VERSION ""

NS_ :

BS_:

BU_:
VAL_TABLE_ vtSig_SystemMode 3 "Autonomous Mode" 2 "Lateral Control" 1 "Longitudinal Control" 0 "Off" ;
VAL_TABLE_ vtGearPosition 12 "IntermediatePosition" 11 "SportsMode" 10 "6" 9 "5" 8 "4" 7 "3" 6 "2" 5 "1" 4 "D" 3 "L" 2 "R" 1 "N" 0 "P" ;

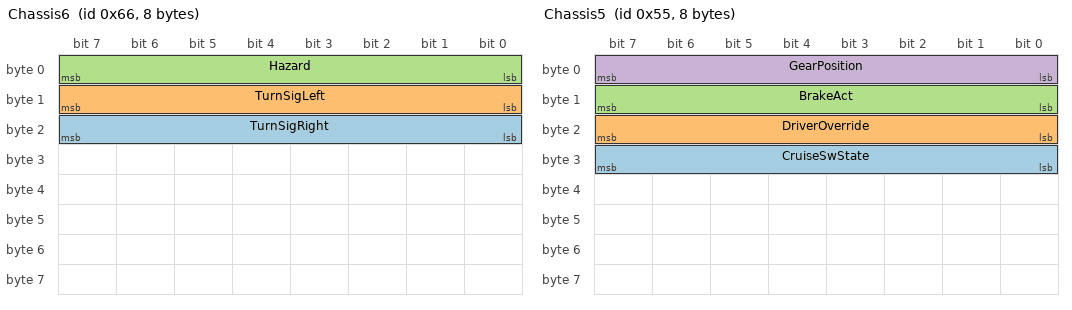
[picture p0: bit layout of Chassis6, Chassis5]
BO_ 102 Chassis6: 8 Vector__XXX
 SG_ TurnSigRight : 16|8@1+ (1,0) [0|0] "" Vector__XXX
 SG_ TurnSigLeft : 8|8@1+ (1,0) [0|0] "" Vector__XXX
 SG_ Hazard : 0|8@1+ (1,0) [0|0] "" Vector__XXX

BO_ 85 Chassis5: 8 Vector__XXX
 SG_ CruiseSwState : 24|8@1+ (1,0) [0|0] "" Vector__XXX
 SG_ DriverOverride : 16|8@1+ (1,0) [0|2] "" Vector__XXX
 SG_ BrakeAct : 8|8@1+ (1,0) [0|0] "" Vector__XXX
 SG_ GearPosition : 0|8@1+ (1,0) [0|0] "" Vector__XXX

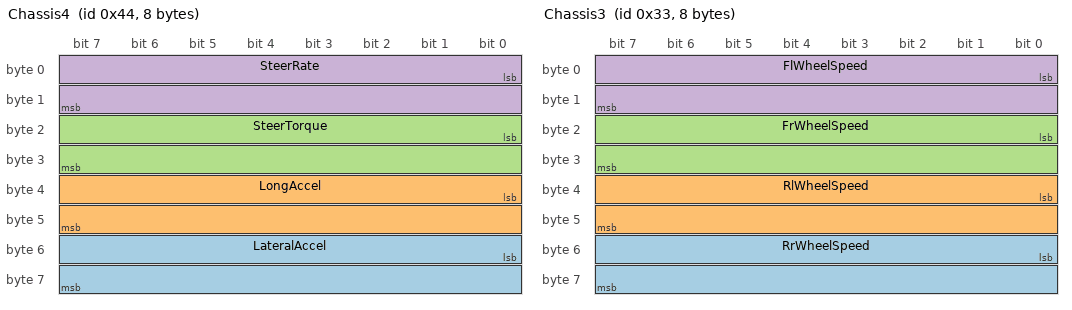
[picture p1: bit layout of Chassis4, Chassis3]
BO_ 68 Chassis4: 8 Vector__XXX
 SG_ LateralAccel : 48|16@1- (0.01,0) [0|0] "" Vector__XXX
 SG_ LongAccel : 32|16@1- (0.01,0) [0|0] "" Vector__XXX
 SG_ SteerTorque : 16|16@1- (0.01,0) [0|0] "N/m" Vector__XXX
 SG_ SteerRate : 0|16@1+ (1,0) [0|0] "deg/s" Vector__XXX

BO_ 51 Chassis3: 8 Vector__XXX
 SG_ RrWheelSpeed : 48|16@1+ (0.1,0) [0|0] "kph" Vector__XXX
 SG_ RlWheelSpeed : 32|16@1+ (0.1,0) [0|0] "kph" Vector__XXX
 SG_ FrWheelSpeed : 16|16@1+ (0.1,0) [0|0] "kph" Vector__XXX
 SG_ FlWheelSpeed : 0|16@1+ (0.1,0) [0|0] "kph" Vector__XXX

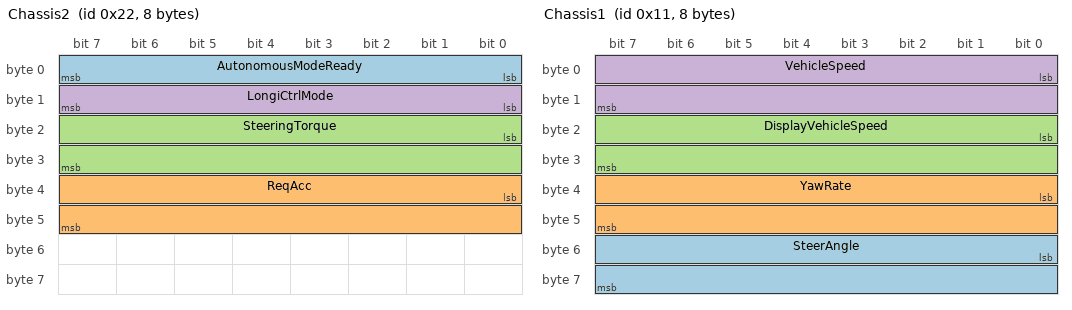
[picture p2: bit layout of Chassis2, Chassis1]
BO_ 34 Chassis2: 8 Vector__XXX
 SG_ AutonomousModeReady : 0|8@1+ (1,0) [0|0] "" Vector__XXX
 SG_ ReqAcc : 32|16@1- (0.01,0) [0|0] "m/s2" Vector__XXX
 SG_ SteeringTorque : 16|16@1- (0.001,0) [0|0] "Nm" Vector__XXX
 SG_ LongiCtrlMode : 8|8@1+ (1,0) [0|0] "" Vector__XXX

BO_ 17 Chassis1: 8 Vector__XXX
 SG_ SteerAngle : 48|16@1- (0.1,0) [0|0] "deg" Vector__XXX
 SG_ YawRate : 32|16@1- (0.01,0) [0|0] "deg/s" Vector__XXX
 SG_ DisplayVehicleSpeed : 16|16@1+ (0.1,0) [0|0] "kph" Vector__XXX
 SG_ VehicleSpeed : 0|16@1+ (0.1,0) [0|0] "kph" Vector__XXX

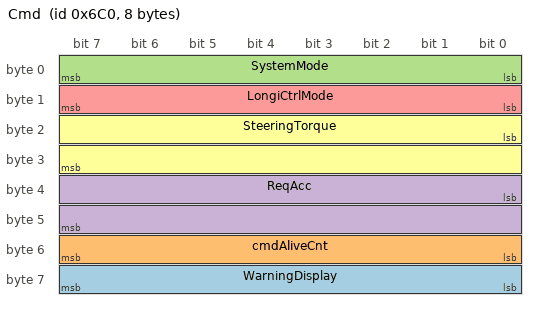
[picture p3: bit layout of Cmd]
BO_ 1728 Cmd: 8 Vector__XXX
 SG_ WarningDisplay : 56|8@1+ (1,0) [0|0] "" Vector__XXX
 SG_ cmdAliveCnt : 48|8@1+ (1,0) [0|255] "" Vector__XXX
 SG_ SystemMode : 0|8@1+ (1,0) [0|0] "" Vector__XXX
 SG_ ReqAcc : 32|16@1- (0.01,0) [-1|1] "m/s2" Vector__XXX
 SG_ LongiCtrlMode : 8|8@1+ (1,0) [0|0] "" Vector__XXX
 SG_ SteeringTorque : 16|16@1- (0.001,0) [-7.5|7.5] "Nm" Vector__XXX

BA_DEF_ BO_  "GenMsgTimeoutTime" INT 0 15000;
BA_DEF_ BU_  "TpUseFC" INT 0 1;
BA_DEF_ BU_  "TpNodeBaseAddress" HEX 0 2047;
BA_DEF_ BU_  "TpCanBus" HEX 1 2;
BA_DEF_ BU_  "TpRxMask" HEX 0 2047;
BA_DEF_ BU_  "TpRxIdentifer" HEX 0 2047;
BA_DEF_ BU_  "TpTxIdentifier" HEX 0 2047;
BA_DEF_  "TpBaseAddress" HEX 0 2047;
BA_DEF_ SG_  "GenSigEnvVarType" ENUM  "Int","Float","Undef";
BA_DEF_ SG_  "GenSigEVName" STRING ;
BA_DEF_ SG_  "GenSigSendType" ENUM  "Cyclic","OnWrite","OnWriteWithRepetition","OnChange","OnChangeWithRepetition","IfActive","IfActiveWithRepetition","NoSigSendType";
BA_DEF_ SG_  "GwSigLatencyTime" INT 0 65535;
BA_DEF_ SG_  "GwSigMissingSourceType" ENUM  "Undef","OldValue","DefaultValue","InitialValue";
BA_DEF_ SG_  "SignalCategory" HEX 10 15;
BA_DEF_ SG_  "UsrSigClass" ENUM  "undef","S","C";
BA_DEF_ SG_  "UsrSigDefinition" STRING ;
BA_DEF_ SG_  "UsrSigNwRequestTime" STRING ;
BA_DEF_ SG_  "UsrSigPurpose" ENUM  "undef","FN","DIAG","DEV","NM";
BA_DEF_ SG_  "UsrSigSendType" ENUM  "Undef","P","E","W","PE","PA";
BA_DEF_ SG_  "UsrSigStartValue" STRING ;
BA_DEF_ SG_  "UsrSigTimeoutTime" STRING ;
BA_DEF_ SG_  "UsrSigTimeoutValue" STRING ;
BA_DEF_ SG_  "UsrSigValidity" ENUM  "B+","ACC","IG","IG1","IG2","Undef";
BA_DEF_ BO_  "GenMsgCycleTime" INT 0 2000;
BA_DEF_ BO_  "GenMsgCycleTimeFast" INT 0 500;
BA_DEF_ BO_  "GenMsgDelayTime" INT 0 20;
BA_DEF_ BO_  "GenMsgILSupport" ENUM  "No","Yes";
BA_DEF_ BO_  "GenMsgSendType" ENUM  "FixedPeriodic","Event","EnabledPeriodic","not_used","not_used","EventPeriodic","not_used","not_used","NoMsgSendType";
BA_DEF_ BU_  "GenNodSleepTime" INT 1375 1650;
BA_DEF_ BU_  "ILUsed" ENUM  "No","Yes";
BA_DEF_ BU_  "NmCAN" INT 1 2;
BA_DEF_ BU_  "NodeLayerModules" STRING ;
BA_DEF_  "Baudrate" INT 50000 1000000;
BA_DEF_  "BusType" STRING ;
BA_DEF_  "GenEnvVarEndingDsp" STRING ;
BA_DEF_  "GenEnvVarEndingSnd" STRING ;
BA_DEF_  "GenEnvVarPrefix" STRING ;
BA_DEF_  "GenNWMApBusSleep" STRING ;
BA_DEF_  "GenNWMApCanNormal" STRING ;
BA_DEF_  "GenNWMApCanOff" STRING ;
BA_DEF_  "GenNWMApCanOn" STRING ;
BA_DEF_  "GenNWMApCanSleep" STRING ;
BA_DEF_  "GenNWMApCanWakeUp" STRING ;
BA_DEF_  "GenNWMApIndRingData" STRING ;
BA_DEF_  "GenNWMGotoMode_Awake" STRING ;
BA_DEF_  "GenNWMGotoMode_BusSleep" STRING ;
BA_DEF_  "GenNWMSleepTime" INT 1375 1650;
BA_DEF_  "GenNWMTalkNM" STRING ;
BA_DEF_  "Manufacturer" STRING ;
BA_DEF_  "NmBaseAddress" HEX 0 2047;
BA_DEF_  "NmMessageCount" INT 0 128;
BA_DEF_  "NmType" STRING ;
BA_DEF_  "SamplePointMax" INT 50 85;
BA_DEF_  "SamplePointMin" INT 55 85;
BA_DEF_  "SyncJumpWidthMax" INT 1 8;
BA_DEF_  "SyncJumpWidthMin" INT 1 4;
BA_DEF_  "VersionDay" INT 1 31;
BA_DEF_  "VersionMonth" INT 1 12;
BA_DEF_  "VersionWeek" INT 1 53;
BA_DEF_  "VersionYear" INT 0 9999;
BA_DEF_REL_ BU_SG_REL_  "GenSigTimeoutTime" INT 0 7000;
BA_DEF_DEF_  "GenMsgTimeoutTime" 150;
BA_DEF_DEF_  "TpUseFC" 1;
BA_DEF_DEF_  "TpNodeBaseAddress" 1536;
BA_DEF_DEF_  "TpCanBus" 1;
BA_DEF_DEF_  "TpRxMask" 2047;
BA_DEF_DEF_  "TpRxIdentifer" 1984;
BA_DEF_DEF_  "TpTxIdentifier" 1968;
BA_DEF_DEF_  "TpBaseAddress" 1536;
BA_DEF_DEF_  "GenSigEnvVarType" "Undef";
BA_DEF_DEF_  "GenSigEVName" "@Signame";
BA_DEF_DEF_  "GenSigSendType" "NoSigSendType";
BA_DEF_DEF_  "GwSigLatencyTime" 40;
BA_DEF_DEF_  "GwSigMissingSourceType" "Undef";
BA_DEF_DEF_  "SignalCategory" 12;
BA_DEF_DEF_  "UsrSigClass" "undef";
BA_DEF_DEF_  "UsrSigDefinition" "Undef";
BA_DEF_DEF_  "UsrSigNwRequestTime" "Undef";
BA_DEF_DEF_  "UsrSigPurpose" "undef";
BA_DEF_DEF_  "UsrSigSendType" "P";
BA_DEF_DEF_  "UsrSigStartValue" "Undef";
BA_DEF_DEF_  "UsrSigTimeoutTime" "500";
BA_DEF_DEF_  "UsrSigTimeoutValue" "Undef";
BA_DEF_DEF_  "UsrSigValidity" "IG";
BA_DEF_DEF_  "GenMsgCycleTime" 10;
BA_DEF_DEF_  "GenMsgCycleTimeFast" 40;
BA_DEF_DEF_  "GenMsgDelayTime" 20;
BA_DEF_DEF_  "GenMsgILSupport" "Yes";
BA_DEF_DEF_  "GenMsgSendType" "FixedPeriodic";
BA_DEF_DEF_  "GenNodSleepTime" 1500;
BA_DEF_DEF_  "ILUsed" "Yes";
BA_DEF_DEF_  "NmCAN" 1;
BA_DEF_DEF_  "NodeLayerModules" "oseknm01.dll";
BA_DEF_DEF_  "Baudrate" 500000;
BA_DEF_DEF_  "BusType" "CAN";
BA_DEF_DEF_  "GenEnvVarEndingDsp" "Dsp_";
BA_DEF_DEF_  "GenEnvVarEndingSnd" "_";
BA_DEF_DEF_  "GenEnvVarPrefix" "Env";
BA_DEF_DEF_  "GenNWMApBusSleep" "ApplNmCanBusSleep()";
BA_DEF_DEF_  "GenNWMApCanNormal" "ApplNmCanNormal()";
BA_DEF_DEF_  "GenNWMApCanOff" "ApplCanOffline()";
BA_DEF_DEF_  "GenNWMApCanOn" "ApplCanOnline()";
BA_DEF_DEF_  "GenNWMApCanSleep" "ApplNmCanSleep()";
BA_DEF_DEF_  "GenNWMApCanWakeUp" "ApplCanWakeUp()";
BA_DEF_DEF_  "GenNWMApIndRingData" "apIndRingData()";
BA_DEF_DEF_  "GenNWMGotoMode_Awake" "GotoMode_Awake()";
BA_DEF_DEF_  "GenNWMGotoMode_BusSleep" "GotoMode_BusSleep()";
BA_DEF_DEF_  "GenNWMSleepTime" 1500;
BA_DEF_DEF_  "GenNWMTalkNM" "TalkNM()";
BA_DEF_DEF_  "Manufacturer" "HMC";
BA_DEF_DEF_  "NmBaseAddress" 1024;
BA_DEF_DEF_  "NmMessageCount" 128;
BA_DEF_DEF_  "NmType" "Vector";
BA_DEF_DEF_  "SamplePointMax" 82;
BA_DEF_DEF_  "SamplePointMin" 75;
BA_DEF_DEF_  "SyncJumpWidthMax" 3;
BA_DEF_DEF_  "SyncJumpWidthMin" 2;
BA_DEF_DEF_  "VersionDay" 1;
BA_DEF_DEF_  "VersionMonth" 1;
BA_DEF_DEF_  "VersionWeek" 1;
BA_DEF_DEF_  "VersionYear" 2010;
BA_DEF_DEF_REL_ "GenSigTimeoutTime" 500;
VAL_ 85 CruiseSwState 4 "Cancel" 3 "Time gap" 2 "Set/Minus" 1 "Resume/Plus" 0 "Idle Position" ;
VAL_ 85 GearPosition 12 "IntermediatePosition" 11 "SportsMode" 10 "6" 9 "5" 8 "4" 7 "3" 6 "2" 5 "1" 4 "D" 3 "L" 2 "R" 1 "N" 0 "P" ;
VAL_ 1728 SystemMode 3 "Autonomous Mode" 2 "Lateral Control" 1 "Longitudinal Control" 0 "Off" ;
VAL_ 1728 LongiCtrlMode 1 "LongCtrl_AEB" 0 "LongCtrl_ACC" ;
